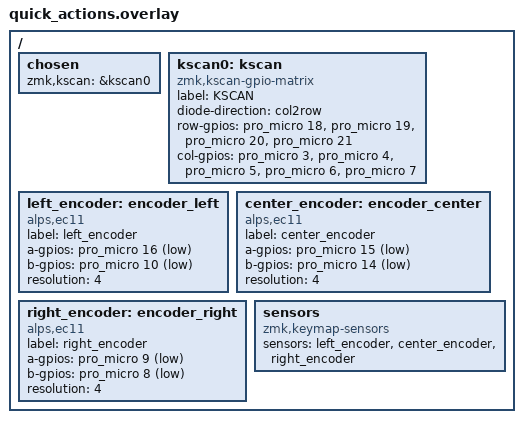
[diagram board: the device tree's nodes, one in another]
/*
 * Copyright (c) 2022 The ZMK Contributors
 *
 * SPDX-License-Identifier: MIT
 */

#include <dt-bindings/zmk/matrix_transform.h>

/ {
    chosen {
        zmk,kscan = &kscan0;
    };

    kscan0: kscan {
        compatible = "zmk,kscan-gpio-matrix";
        label = "KSCAN";
        diode-direction = "col2row";

         row-gpios
            = <&pro_micro 18 (GPIO_ACTIVE_HIGH | GPIO_PULL_DOWN)>
            , <&pro_micro 19 (GPIO_ACTIVE_HIGH | GPIO_PULL_DOWN)>
            , <&pro_micro 20 (GPIO_ACTIVE_HIGH | GPIO_PULL_DOWN)>
            , <&pro_micro 21 (GPIO_ACTIVE_HIGH | GPIO_PULL_DOWN)>
            ;

        col-gpios
            = <&pro_micro 3 GPIO_ACTIVE_HIGH>
            , <&pro_micro 4 GPIO_ACTIVE_HIGH>
            , <&pro_micro 5 GPIO_ACTIVE_HIGH>
            , <&pro_micro 6 GPIO_ACTIVE_HIGH>
            , <&pro_micro 7 GPIO_ACTIVE_HIGH>
            ;
    };


    left_encoder: encoder_left {
        compatible = "alps,ec11";
        label = "left_encoder";
        a-gpios = <&pro_micro 16 (GPIO_ACTIVE_LOW | GPIO_PULL_UP)>;
        b-gpios = <&pro_micro 10 (GPIO_ACTIVE_LOW | GPIO_PULL_UP)>;
        resolution = <4>;
        status = "okay";
    };

    center_encoder: encoder_center {
        compatible = "alps,ec11";
        label = "center_encoder";
        a-gpios = <&pro_micro 15 (GPIO_ACTIVE_LOW | GPIO_PULL_UP)>;
        b-gpios = <&pro_micro 14 (GPIO_ACTIVE_LOW | GPIO_PULL_UP)>;
        resolution = <4>;
        status = "okay";
    };
		
    right_encoder: encoder_right {
        compatible = "alps,ec11";
        label = "right_encoder";
        a-gpios = <&pro_micro 9 (GPIO_ACTIVE_LOW | GPIO_PULL_UP)>;
        b-gpios = <&pro_micro 8 (GPIO_ACTIVE_LOW | GPIO_PULL_UP)>;
        resolution = <4>;
        status = "okay";
    };

    sensors {
        compatible = "zmk,keymap-sensors";
        sensors = <&left_encoder &center_encoder &right_encoder>;
    };
};
